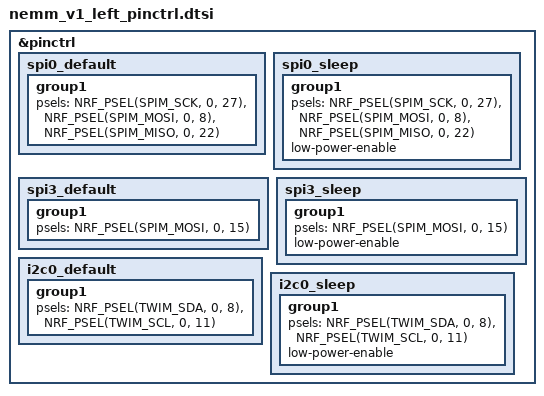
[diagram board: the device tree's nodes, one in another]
/*
# Copyright (c) 2021 The ZMK Contributors
*
* SPDX-License-Identifier: MIT
*/

#include <dt-bindings/led/led.h>

&pinctrl {
	spi0_default: spi0_default {
		group1 {
			psels = <NRF_PSEL(SPIM_SCK, 0, 27)>,
				    <NRF_PSEL(SPIM_MOSI, 0, 8)>,
				    <NRF_PSEL(SPIM_MISO, 0, 22)>;
		};
	};

	spi0_sleep: spi0_sleep {
		group1 {
			psels = <NRF_PSEL(SPIM_SCK, 0, 27)>,
				    <NRF_PSEL(SPIM_MOSI, 0, 8)>,
				    <NRF_PSEL(SPIM_MISO, 0, 22)>;
			low-power-enable;
		};
	};

	spi3_default: spi3_default {
        group1 {
            psels = <NRF_PSEL(SPIM_MOSI, 0, 15)>;
        };
    };

    spi3_sleep: spi3_sleep {
        group1 {
            psels = <NRF_PSEL(SPIM_MOSI, 0, 15)>;
            low-power-enable;
        };
    };

	i2c0_default: i2c0_default {
		group1 {
			psels = <NRF_PSEL(TWIM_SDA, 0, 8)>,
				    <NRF_PSEL(TWIM_SCL, 0, 11)>;
		};
	};

	i2c0_sleep: i2c0_sleep {
		group1 {
			psels = <NRF_PSEL(TWIM_SDA, 0, 8)>,
				    <NRF_PSEL(TWIM_SCL, 0, 11)>;
			low-power-enable;
		};
	};
};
